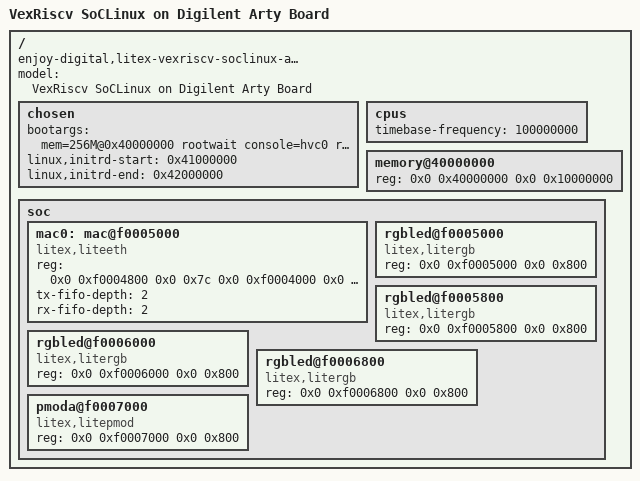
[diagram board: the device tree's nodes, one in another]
/include/ "testsoc-linux.dtsi"

/ {
	compatible = "enjoy-digital,litex-vexriscv-soclinux-arty", "enjoy-digital,litex-vexriscv-soclinux";
	model = "VexRiscv SoCLinux on Digilent Arty Board";

	chosen {
		bootargs = "mem=256M@0x40000000 rootwait console=hvc0 root=/dev/ram0 init=/sbin/init swiotlb=32";
		linux,initrd-start = <0x41000000>;
		linux,initrd-end   = <0x42000000>; // max 16MB ramdisk image
	};

	cpus {
		timebase-frequency = <100000000>;
	};

	memory@40000000 {
		device_type = "memory";
		reg = <0x0 0x40000000 0x0 0x10000000>;
	};

	soc {
        mac0: mac@f0005000 {
            compatible = "litex,liteeth";
            reg = < 0x0 0xf0004800 0x0 0x7c     // ethmac CSR
                    0x0 0xf0004000 0x0 0x0a     // ethphy
                    0x0 0x80000000 0x0 0x2000>; // ethmac buffer
            tx-fifo-depth = <2>;
            rx-fifo-depth = <2>;
        };
        rgbled@f0005000 {
           compatible = "litex,litergb";
           reg = <0x0 0xf0005000 0x0 0x800>;
        };
        rgbled@f0005800 {
           compatible = "litex,litergb";
           reg = <0x0 0xf0005800 0x0 0x800>;
        };
        rgbled@f0006000 {
           compatible = "litex,litergb";
           reg = <0x0 0xf0006000 0x0 0x800>;
        };
        rgbled@f0006800 {
           compatible = "litex,litergb";
           reg = <0x0 0xf0006800 0x0 0x800>;
        };
    		pmoda@f0007000 {
           compatible = "litex,litepmod";
           reg = <0x0 0xf0007000 0x0 0x800>;
       };
    };
};
